# RZT2ME register map
Vendor: Renesas Electronics Corporation; Series: RZT; File version: 1.00.00
CPU: other r0p0, little endian, MPU, no FPU, VTOR, 4 interrupt priority bits, 624 interrupts
Registers are 32-bit, read-write, reset 0x0 unless marked. A register's access mark holds for its fields unless they carry their own. Offsets are from the block's base; [hi:lo] are bit positions; {n}, {i} and the like mark numbered series; 'fields as' and 'values as' point back to an identical list.

## CANFD (part 1 of 2)
Base 0x80020000
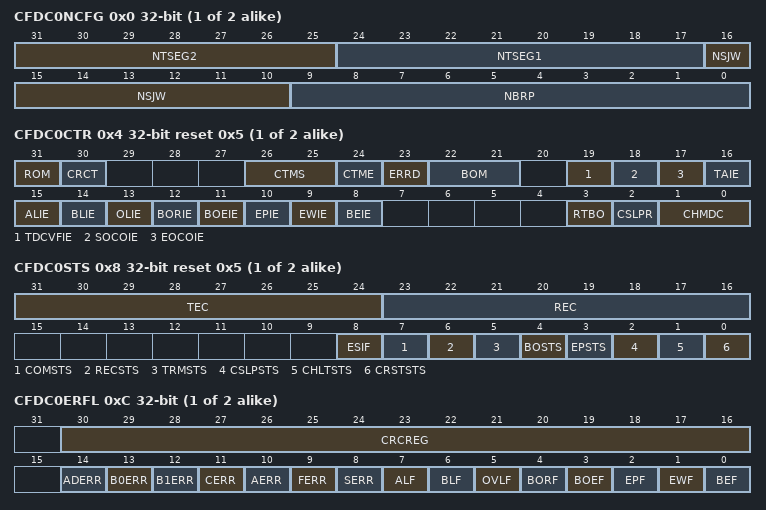
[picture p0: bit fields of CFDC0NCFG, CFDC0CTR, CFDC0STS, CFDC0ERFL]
{0x0+0x10*i} CFDC{i}NCFG (i=0..1) — Channel {i} Nominal Bit Rate Configuration Register
  [31:25] NTSEG2 — Nominal Bit Rate Time Segment 2 Control
  [24:17] NTSEG1 — Nominal Bit Rate Time Segment 1 Control
  [16:10] NSJW — Nominal Bit Rate Resynchronization Jump Width Control
  [9:0] NBRP — Nominal Bit Rate Prescaler
{0x4+0x10*i} CFDC{i}CTR (i=0..1) reset 0x5 — Channel {i} Control Register
  [31] ROM — Restricted Operation Mode Enable
    0=Restricted operation mode disabled; 1=Restricted operation mode enabled
  [30] CRCT — CRC Error Test Enable
    0=The first bit of reception ID field is not inverted; 1=The first bit of reception ID field is inverted
  [26:25] CTMS — Communication Test Mode Select
    0=Standard test mode; 1=Listen-only mode; 2=Self-test mode 0 (External loopback mode); 3=Self-test mode 1 (Internal loopback mode)
  [24] CTME — Communication Test Mode Enable
    0=Communication test mode is disabled; 1=Communication test mode is enabled
  [23] ERRD — Error Display Mode Select
    0=Error flags are displayed only for the first error information after bits [14:8] in the CFDCnERFL register are all cleared; 1=Error flag for all error information are displayed
  [22:21] BOM — Bus-Off Recovery Mode Select
    0=ISO11898-1 compliant; 1=Entry to Channel Halt mode automatically at bus-off entry; 2=Entry to Channel Halt mode automatically at bus-off end; 3=Entry to Channel Halt mode (in bus-off state) by program request
  [19] TDCVFIE — Transceiver Delay Compensation Violation Interrupt Enable
    0=Transceiver delay compensation violation interrupt disabled; 1=Transceiver delay compensation violation interrupt enabled
  [18] SOCOIE — Successful Occurrence Counter Overflow Interrupt Enable
    0=Successful occurrence counter overflow interrupt disabled; 1=Successful occurrence counter overflow interrupt enabled
  [17] EOCOIE — Error Occurrence Counter Overflow Interrupt Enable
    0=Error occurrence counter overflow interrupt disabled; 1=Error occurrence counter overflow interrupt enabled
  [16] TAIE — Transmission Abort Interrupt Enable
    0=Transmission abort interrupt disabled; 1=Transmission abort interrupt enabled
  [15] ALIE — Arbitration Lost Interrupt Enable
    0=Arbitration lost interrupt disabled; 1=Arbitration lost interrupt enabled
  [14] BLIE — Bus Lock Interrupt Enable
    0=Bus lock interrupt disabled; 1=Bus lock interrupt enabled
  [13] OLIE — Overload Interrupt Enable
    0=Overload interrupt disabled; 1=Overload interrupt enabled
  [12] BORIE — Bus-Off Recovery Interrupt Enable
    0=Bus-off recovery interrupt disabled; 1=Bus-off recovery interrupt enabled
  [11] BOEIE — Bus-Off Entry Interrupt Enable
    0=Bus-off entry interrupt disabled; 1=Bus-off entry interrupt enabled
  [10] EPIE — Error Passive Interrupt Enable
    0=Error passive interrupt disabled; 1=Error passive interrupt enabled
  [9] EWIE — Error Warning Interrupt Enable
    0=Error warning interrupt disabled; 1=Error warning interrupt enabled
  [8] BEIE — Bus Error Interrupt Enable
    0=Bus error interrupt disabled; 1=Bus error interrupt enabled
  [3] RTBO — Forcible Return from Bus-Off
  [2] CSLPR — Channel Stop Mode
    0=Other than Channel Stop mode; 1=Channel Stop mode
  [1:0] CHMDC — Mode Select
    0=Channel Communication mode; 1=Channel Reset mode; 2=Channel Halt mode; 3=Setting prohibited
{0x8+0x10*i} CFDC{i}STS (i=0..1) reset 0x5 — Channel {i} Status Register
  [31:24] TEC ro — Transmission Error Count
  [23:16] REC ro — Reception Error Count
  [8] ESIF — Error State Indication Flag
    0=No CANFD message whose ESI bit is recessive has been received; 1=At least one CANFD message whose ESI bit is recessive has been received
  [7] COMSTS ro — Communication Status Flag
    0=Communication is not ready; 1=Communication is ready
  [6] RECSTS ro — Receive Status Flag
    0=Bus idle, in transmission or bus off state; 1=In reception
  [5] TRMSTS ro — Transmit Status Flag
    0=Bus idle or in reception; 1=In transmission or bus off state
  [4] BOSTS ro — Bus-Off Status Flag
    0=Not in bus-off state; 1=In bus-off state
  [3] EPSTS ro — Error Passive Status Flag
    0=Not in error passive state; 1=In error passive state
  [2] CSLPSTS ro — Channel Stop Status Flag
    0=Not in Channel Sleep mode; 1=In Channel Sleep mode
  [1] CHLTSTS ro — Channel Halt Status Flag
    0=Not in Channel Halt mode; 1=In Channel Halt mode
  [0] CRSTSTS ro — Channel Reset Status Flag
    0=Not in Channel Reset mode; 1=In Channel Reset mode
{0xC+0x10*i} CFDC{i}ERFL (i=0..1) — Channel {i} Error Flag Register
  [30:16] CRCREG ro — CRC Calculation Data (CRC length: 15 bits)
  [14] ADERR — Acknowledge Delimiter Error Flag
    0=Channel acknowledge delimiter error not detected; 1=Channel acknowledge delimiter error detected
  [13] B0ERR — Dominant Bit Error Flag
    0=Channel dominant bit error not detected; 1=Channel dominant bit error detected
  [12] B1ERR — Recessive Bit Error Flag
    0=Channel recessive bit error not detected; 1=Channel recessive bit error detected
  [11] CERR — CRC Error Flag
    0=Channel CRC error not detected; 1=Channel CRC error detected
  [10] AERR — Acknowledge Error Flag
    0=Channel acknowledge error not detected; 1=Channel acknowledge error detected
  [9] FERR — Form Error Flag
    0=Channel form error not detected; 1=Channel form error detected
  [8] SERR — Stuff Error Flag
    0=Channel stuff error not detected; 1=Channel stuff error detected
  [7] ALF — Arbitration Lost Flag
    0=Channel arbitration-lost not detected; 1=Channel arbitration-lost detected
  [6] BLF — Bus Lock Flag
    0=Channel bus lock not detected; 1=Channel bus lock detected
  [5] OVLF — Overload Flag
    0=Channel overload not detected; 1=Channel overload detected
  [4] BORF — Bus-Off Recovery Flag
    0=Channel bus-off recovery not detected; 1=Channel bus-off recovery detected
  [3] BOEF — Bus-Off Entry Flag
    0=Channel bus-off entry not detected; 1=Channel bus-off entry detected
  [2] EPF — Error Passive Flag
    0=Channel error passive not detected; 1=Channel error passive detected
  [1] EWF — Error Warning Flag
    0=Channel error warning not detected; 1=Channel error warning detected
  [0] BEF — Bus Error Flag
    0=Channel bus error not detected; 1=Channel bus error detected
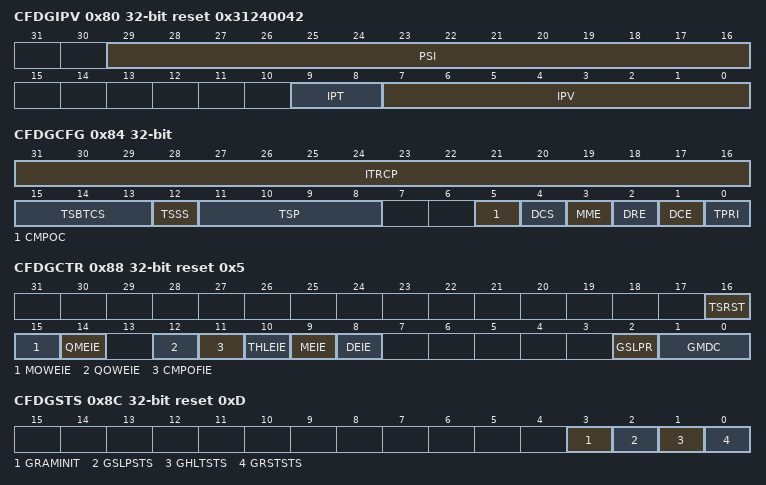
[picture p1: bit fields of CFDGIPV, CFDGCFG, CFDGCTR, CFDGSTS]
0x80 CFDGIPV ro reset 0x31240042 (reset mask 0xFFFFFEFF) — Global IP Version Register
  [29:16] PSI — Parameter Status Information
  [9:8] IPT — IP Type
    0=CAN IP; 1=CAN-FD IP
  [7:0] IPV — IP Version
0x84 CFDGCFG — Global Configuration Register
  [31:16] ITRCP — Interval Timer Reference Clock Prescaler
  [15:13] TSBTCS — Timestamp Bit Time Channel Select
    0=Select clock from channel 0; 1=Select clock from channel 1; other=Others (Setting prohibited)
  [12] TSSS — Timestamp Source Select
    0=Source clock for timestamp counter is peripheral clock; 1=Source clock for timestamp counter is bit time clock
  [11:8] TSP — Timestamp Prescaler
  [5] CMPOC — CAN-FD Message Payload Overflow Configuration
    0=Message is rejected; 1=Message payload is cut to fit to configured message size
  [4] DCS — Data Link Controller Clock Select
    0=PCLKM; 1=PCLKCAN
  [3] MME — Mirror Mode Enable
    0=Mirror mode disabled; 1=Mirror mode enabled
  [2] DRE — DLC Replacement Enable
    0=DLC replacement disabled; 1=DLC replacement enabled
  [1] DCE — DLC Check Enable
    0=DLC check disabled; 1=DLC check enabled
  [0] TPRI — Transmission Priority
    0=ID priority; 1=Message buffer number priority
0x88 CFDGCTR reset 0x5 — Global Control Register
  [16] TSRST — Timestamp Reset
    0=Timestamp not reset; 1=Timestamp reset
  [15] MOWEIE — Message Lost Error Interrupt Enable
    0=GW FIFO message lost error interrupt disabled; 1=GW FIFO message lost error interrupt enabled
  [14] QMEIE — TXQ Message Lost Error Interrupt Enable
    0=TXQ message lost error interrupt disabled; 1=TXQ message lost error interrupt enabled
  [12] QOWEIE — TXQ Message Overwrite Error Interrupt Enable
    0=TXQ message overwrite error interrupt disabled; 1=TXQ message overwrite error interrupt enabled
  [11] CMPOFIE — CAN-FD Message Payload Overflow Flag Interrupt Enable
    0=CAN-FD message payload overflow flag interrupt disabled; 1=CAN-FD message payload overflow flag interrupt enabled
  [10] THLEIE — TX History List Entry Lost Interrupt Enable
    0=TX history list entry lost interrupt disabled; 1=TX history list entry lost interrupt enabled
  [9] MEIE — Message Lost Error Interrupt Enable
    0=Message lost error interrupt disabled; 1=Message lost error interrupt enabled
  [8] DEIE — DLC Check Interrupt Enable
    0=DLC check interrupt disabled; 1=DLC check interrupt enabled
  [2] GSLPR — Global Sleep Request
    0=Global sleep request disabled; 1=Global sleep request enabled
  [1:0] GMDC — Global Mode Control
    0=Global operation mode request; 1=Global reset mode request; 2=Global halt mode request; 3=Keep current value
0x8C CFDGSTS ro reset 0xD — Global Status Register
  [3] GRAMINIT — Global RAM Initialization
    0=RAM initialization is complete; 1=RAM initialization is ongoing
  [2] GSLPSTS — Global Sleep Status
    0=Not in Sleep mode; 1=In Sleep mode
  [1] GHLTSTS — Global Halt Status
    0=Not in Halt mode; 1=In Halt mode
  [0] GRSTSTS — Global Reset Status
    0=Not in Reset mode; 1=In Reset mode
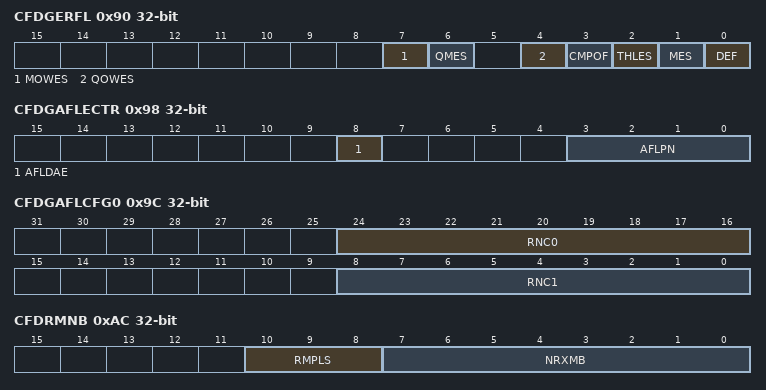
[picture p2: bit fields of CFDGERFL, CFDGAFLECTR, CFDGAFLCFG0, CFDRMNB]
0x90 CFDGERFL — Global Error Flag Register
  [7] MOWES ro — Message Overwrite Error Status
    0=Message overwrite error not detected; 1=Message overwrite error detected
  [6] QMES ro — TXQ Message Lost Error Status
    0=TXQ message lost error not detected; 1=TXQ message lost error detected
  [4] QOWES ro — TXQ Message Overwrite Error Status
    0=TXQ message overwrite error not detected; 1=TXQ message overwrite error detected
  [3] CMPOF — CAN-FD Message Payload Overflow Flag
    0=CAN-FD message payload overflow not detected; 1=CAN-FD message payload overflow detected
  [2] THLES ro — TX History List Entry Lost Error Status
    0=TX history list entry lost error not detected; 1=TX history list entry lost error detected
  [1] MES ro — Message Lost Error Status
    0=Message lost error not detected; 1=Message lost error detected
  [0] DEF — DLC Error Flag
    0=DLC error not detected; 1=DLC error detected
0x94 CFDGTSC ro — Global Timestamp Counter Register
  [15:0] TS — Timestamp value
0x98 CFDGAFLECTR — Global Acceptance Filter List Entry Control Register
  [8] AFLDAE — Acceptance Filter List Data Access Enable
    0=Acceptance Filter List data access disabled; 1=Acceptance Filter List data access enabled
  [3:0] AFLPN — Acceptance Filter List Page Number
0x9C CFDGAFLCFG0 — Global Acceptance Filter List Configuration Register 0
  [24:16] RNC0 — Rule Number for Channel 0
  [8:0] RNC1 — Rule Number for Channel 1
0xAC CFDRMNB — RX Message Buffer Number Register
  [10:8] RMPLS — Reception Message Buffer Payload Data Size
    0=8 bytes; 1=12 bytes; 2=16 bytes; 3=20 bytes; 4=24 bytes; 5=32 bytes; 6=48 bytes; 7=64 bytes
  [7:0] NRXMB — Number of RX Message Buffers
0xB0 CFDRMND0 — RX Message Buffer New Data Register 0
  [31:0] RMNS — RX Message Buffer New Data Status
    0=New data not stored in corresponding RX message buffer; 1=New data stored in corresponding RX message buffer
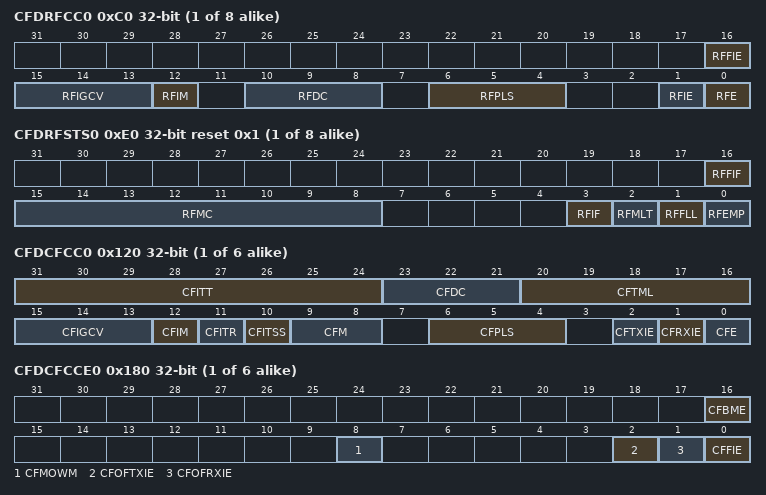
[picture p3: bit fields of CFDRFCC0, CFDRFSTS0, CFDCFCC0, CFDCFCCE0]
{0xC0+4i} CFDRFCC{i} (i=0..7) — RX FIFO Configuration/Control Register {i}
  [16] RFFIE — RX FIFO Full Interrupt Enable
    0=FIFO interrupt generation disabled; 1=FIFO interrupt generation enabled
  [15:13] RFIGCV — RX FIFO Interrupt Generation Counter Value
    0=Interrupt generated when FIFO is 1/8th full; 1=Interrupt generated when FIFO is 1/4th full; 2=Interrupt generated when FIFO is 3/8th full; 3=Interrupt generated when FIFO is 1/2 full; 4=Interrupt generated when FIFO is 5/8th full; 5=Interrupt generated when FIFO is 3/4th full; 6=Interrupt generated when FIFO is 7/8th full; 7=Interrupt generated when FIFO is full
  [12] RFIM — RX FIFO Interrupt Mode
    0=Interrupt generated when RX FIFO counter reaches RFIGCV value from values smaller than RFIGCV; 1=Interrupt generated at the end of every received message storage
  [10:8] RFDC — RX FIFO Depth Configuration
    0=FIFO Depth = 0 messages; 1=FIFO Depth = 4 messages; 2=FIFO Depth = 8 messages; 3=FIFO Depth = 16 messages; 4=FIFO Depth = 32 messages; 5=FIFO Depth = 48 messages; 6=FIFO Depth = 64 messages; 7=FIFO Depth = 128 messages
  [6:4] RFPLS — Rx FIFO Payload Data Size Configuration
    values as CFDRMNB.RMPLS
  [1] RFIE — RX FIFO Interrupt Enable
    values as RFFIE
  [0] RFE — RX FIFO Enable
    0=FIFO disabled; 1=FIFO enabled
{0xE0+4i} CFDRFSTS{i} (i=0..7) reset 0x1 — RX FIFO Status Register {i}
  [16] RFFIF — RX FIFO Full Interrupt Flag
    0=FIFO full interrupt condition not satisfied; 1=FIFO full interrupt condition satisfied
  [15:8] RFMC ro — RX FIFO Message Count
  [3] RFIF — RX FIFO Interrupt Flag
    0=FIFO interrupt condition not satisfied; 1=FIFO interrupt condition satisfied
  [2] RFMLT — RX FIFO Message Lost
    0=No message lost in FIFO; 1=FIFO message lost
  [1] RFFLL ro — RX FIFO Full
    0=FIFO not full; 1=FIFO full
  [0] RFEMP ro — RX FIFO Empty
    0=FIFO not empty; 1=FIFO empty
{0x100+4i} CFDRFPCTR{i} (i=0..7) — RX FIFO Pointer Control Register {i}
  [7:0] RFPC — RX FIFO Pointer Control
{0x120+4i} CFDCFCC{i} (i=0..5) — Common FIFO Configuration/Control Register {i}
  [31:24] CFITT — Common FIFO Interval Transmission Time
  [23:21] CFDC — Common FIFO Depth Configuration
    values as CFDRFCC0.RFDC
  [20:16] CFTML — Common FIFO TX Message Buffer Link
  [15:13] CFIGCV — Common FIFO Interrupt Generation Counter Value
    values as CFDRFCC0.RFIGCV
  [12] CFIM — Common FIFO Interrupt Mode
    0=RX FIFO mode: RX interrupt generated when Common FIFO counter reaches CFIGCV value from a lower value TX FIFO mode: TX interrupt generated when Common FIFO transmits the last message successfully GW FIFO mode: For RX interrupt flag: Interrupt generated when FIFO counter increments and reaches the value configured in CFIGCV For TX interrupt flag: Interrupt generated when FIFO transmits the last message successfully; 1=RX FIFO mode: RX interrupt generated at the end of every received message storage TX FIFO mode: TX interrupt generated for every successfully transmitted message GW FIFO mode: For RX interrupt flag: Interrupt generated when a message is stored in the FIFO For TX interrupt flag: Interrupt generated when a message is successfully transmitted from the FIFO
  [11] CFITR — Common FIFO Interval Timer Resolution
    0=Reference clock period * 1; 1=Reference clock period * 10
  [10] CFITSS — Common FIFO Interval Timer Source Select
    0=Reference clock (* 1 / * 10 period); 1=Bit time clock of related channel (FIFO is linked to fixed channel)
  [9:8] CFM — Common FIFO Mode
    0=RX FIFO mode; 1=TX FIFO mode; 2=CAN - CAN GW FIFO mode
  [6:4] CFPLS — Common FIFO Payload Data Size Configuration
    values as CFDRMNB.RMPLS
  [2] CFTXIE — Common FIFO TX Interrupt Enable
    0=FIFO interrupt generation disabled for Frame TX; 1=FIFO interrupt generation enabled for Frame TX
  [1] CFRXIE — Common FIFO RX Interrupt Enable
    0=FIFO interrupt generation disabled for Frame RX; 1=FIFO interrupt generation enabled for Frame RX
  [0] CFE — Common FIFO Enable
    0=FIFO disabled; 1=FIFO enabled
{0x180+4i} CFDCFCCE{i} (i=0..5) — Common FIFO Configuration/Control Enhancement Register {i}
  [16] CFBME — Common FIFO Buffering Mode Enable
    0=Transmission from Common FIFO; 1=Transmission halt from Common FIFO
  [8] CFMOWM — Common FIFO Message Overwrite Mode
    0=Message discarded mode; 1=Message overwrite mode
  [2] CFOFTXIE — Common FIFO One Frame Transmission Interrupt Enable
    0=One Frame TX interrupt generation disabled; 1=One Frame TX interrupt generation enabled
  [1] CFOFRXIE — Common FIFO One Frame Reception Interrupt Enable
    0=One Frame RX interrupt generation disabled; 1=One Frame RX interrupt generation enabled
  [0] CFFIE — Common FIFO Full Interrupt Enable
    0=FIFO Interrupt generation disabled; 1=FIFO Interrupt generation enabled
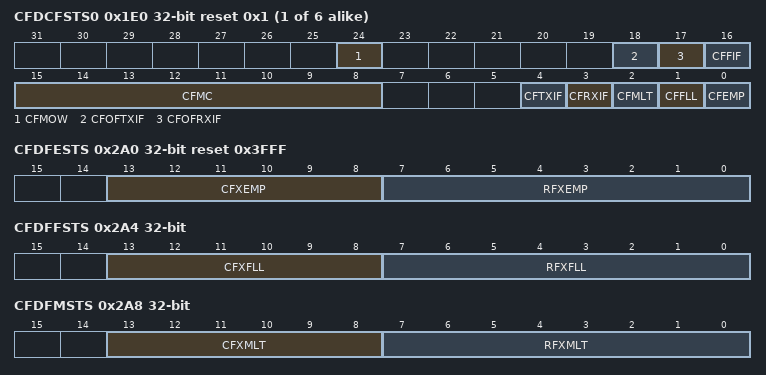
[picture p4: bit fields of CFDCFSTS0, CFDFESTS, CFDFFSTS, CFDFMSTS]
{0x1E0+4i} CFDCFSTS{i} (i=0..5) reset 0x1 — Common FIFO Status Register {i}
  [24] CFMOW — Common FIFO Message Overwrite
    0=No message overwrite occurred in FIFO; 1=Message overwrite occurred in FIFO
  [18] CFOFTXIF — Common FIFO One Frame Transmission Interrupt Flag
  [17] CFOFRXIF — Common FIFO One Frame Reception Interrupt Flag
  [16] CFFIF — Common FIFO Full Interrupt Flag
    0=Interrupt condition not satisfied for FIFO full interrupt; 1=Interrupt condition satisfied for FIFO full interrupt
  [15:8] CFMC ro — Common FIFO Message Count
  [4] CFTXIF — Common TX FIFO Interrupt Flag
    0=FIFO interrupt condition not satisfied after frame transmission; 1=FIFO Interrupt condition satisfied after frame transmission
  [3] CFRXIF — Common RX FIFO Interrupt Flag
    0=FIFO interrupt condition not satisfied after frame reception; 1=FIFO interrupt condition satisfied after frame reception
  [2] CFMLT — Common FIFO Message Lost
    0=FIFO message not lost; 1=FIFO message lost
  [1] CFFLL ro — Common FIFO Full
    0=FIFO not full; 1=FIFO full
  [0] CFEMP ro — Common FIFO Empty
    0=FIFO not empty; 1=FIFO empty
{0x240+4i} CFDCFPCTR{i} (i=0..5) wo — Common FIFO Pointer Control Register {i}
  [7:0] CFPC — Common FIFO Pointer Control
0x2A0 CFDFESTS ro reset 0x3FFF — FIFO Empty Status Register
  [13:8] CFXEMP — Common FIFO Empty Status
    0=Corresponding FIFO not empty; 1=Corresponding FIFO empty
  [7:0] RFXEMP — RX FIFO Empty Status
    0=Corresponding FIFO not empty; 1=Corresponding FIFO empty
0x2A4 CFDFFSTS ro — FIFO Full Status Register
  [13:8] CFXFLL — Common FIFO Full Status
    0=Corresponding FIFO not full; 1=Corresponding FIFO full
  [7:0] RFXFLL — RX FIFO Full Status
    0=Corresponding FIFO not full; 1=Corresponding FIFO full
0x2A8 CFDFMSTS ro — FIFO Message Lost Status Register
  [13:8] CFXMLT — Common FIFO Message Lost Status
    0=Corresponding FIFO Message Lost flag not set; 1=Corresponding FIFO Message Lost flag set
  [7:0] RFXMLT — RX FIFO Message Lost Status
    values as CFXMLT
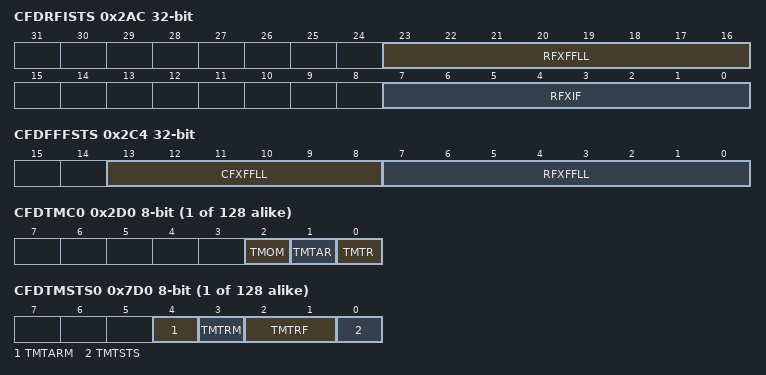
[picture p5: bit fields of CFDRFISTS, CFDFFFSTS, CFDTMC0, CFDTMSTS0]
0x2AC CFDRFISTS ro — RX FIFO Interrupt Flag Status Register
  [23:16] RFXFFLL — RX FIFO[x] Interrupt Full Flag Status
    0=Corresponding RX FIFO Interrupt Full flag not set; 1=Corresponding RX FIFO Interrupt Full flag set
  [7:0] RFXIF — RX FIFO[x] Interrupt Flag Status
    0=Corresponding RX FIFO Interrupt flag not set; 1=Corresponding RX FIFO Interrupt flag set
0x2B0 CFDCFRISTS ro — Common FIFO RX Interrupt Flag Status Register
  [5:0] CFXRXIF — Common FIFO RX Interrupt Flag Status
    0=Corresponding Common FIFO RX Interrupt flag not set; 1=Corresponding Common FIFO RX Interrupt flag set
0x2B4 CFDCFTISTS ro — Common FIFO TX Interrupt Flag Status Register
  [5:0] CFXTXIF — Common FIFO TX Interrupt Flag Status
    0=Corresponding Common FIFO TX Interrupt flag not set; 1=Corresponding Common FIFO TX Interrupt flag set
0x2B8 CFDCFOFRISTS ro — Common FIFO One Frame RX Interrupt Flag Status Register
  [5:0] CFXOFRXIF — Common FIFO One Frame RX Interrupt Flag Status
    0=Corresponding Common FIFO One Frame RX Interrupt flag not set; 1=Corresponding Common FIFO One Frame RX Interrupt flag set
0x2BC CFDCFOFTISTS ro — Common FIFO One Frame TX Interrupt Flag Status Register
  [5:0] CFXOFTXIF — Common FIFO One Frame TX Interrupt Flag Status
    0=Corresponding Common FIFO One Frame TX Interrupt flag not set; 1=Corresponding Common FIFO One Frame TX Interrupt flag set
0x2C0 CFDCFMOWSTS ro — Common FIFO Message Overwrite Status Register
  [5:0] CFXMOW — Common FIFO Massage Overwrite Status
    0=Corresponding FIFO Overwrite flag not set; 1=Corresponding FIFO Overwrite flag set
0x2C4 CFDFFFSTS ro — FIFO FDC Full Status Register
  [13:8] CFXFFLL — COMMON FIFO FDC Level Full Status
    0=Corresponding FIFO full interrupt not set; 1=Corresponding FIFO full interrupt set
  [7:0] RFXFFLL — RX FIFO FDC Level Full Status
    values as CFXFFLL
{0x2D0+i} CFDTMC{i} (i=0..127) 8-bit — TX Message Buffer Control Register {i}
  [2] TMOM — TX Message Buffer One-shot Mode
    0=TX message buffer not configured in one-shot mode; 1=TX message buffer configured in one-shot mode
  [1] TMTAR — TX Message Buffer Transmission Abort Request
    0=TX message buffer transmission request abort not requested; 1=TX message buffer transmission request abort requested
  [0] TMTR — TX Message Buffer Transmission Request
    0=TX Message buffer transmission not requested; 1=TX message buffer transmission requested
{0x7D0+i} CFDTMSTS{i} (i=0..127) 8-bit — TX Message Buffer Status Register {i}
  [4] TMTARM ro — TX Message Buffer Transmission Abort Request Mirrored
    values as CFDTMC0.TMTAR
  [3] TMTRM ro — TX Message Buffer Transmission Request Mirrored
    0=TX message buffer transmission not requested; 1=TX message buffer transmission requested
  [2:1] TMTRF — TX Message Buffer Transmission Result Flag
    0=No result; 1=Transmission aborted from the TX message buffer; 2=Transmission successful from the TX message buffer and transmission abort was not requested; 3=Transmission successful from the TX message buffer and transmission abort was requested
  [0] TMTSTS ro — TX Message Buffer Transmission Status
    0=No on-going transmission; 1=On-going transmission
{0xCD0+4i} CFDTMTRSTS{i} (i=0..3) ro — TX Message Buffer Transmission Request Status Register {i}
  [15:0] TMTRSTS — TX Message Buffer Transmission Request Status
    0=Transmission not requested for corresponding TX message buffer; 1=Transmission requested for corresponding TX message buffer
{0xD70+4i} CFDTMTARSTS{i} (i=0..3) ro — TX Message Buffer Transmission Abort Request Status Register {i}
  [15:0] TMTARSTS — TX Message Buffer Transmission Abort Request Status
    0=Transmission abort not requested for corresponding TX message buffer; 1=Transmission abort requested for corresponding TX message buffer
{0xE10+4i} CFDTMTCSTS{i} (i=0..3) ro — TX Message Buffer Transmission Completion Status Register {i}
  [15:0] TMTCSTS — TX Message Buffer Transmission Completion Status
    0=Transmission not completed for corresponding TX message buffer; 1=Transmission completed for corresponding TX message buffer
{0xEB0+4i} CFDTMTASTS{i} (i=0..3) ro — TX Message Buffer Transmission Abort Status Register {i}
  [15:0] TMTASTS — TX Message Buffer Transmission Abort Status
    0=Transmission not aborted for corresponding TX message buffer; 1=Transmission aborted for corresponding TX message buffer
{0xF50+4i} CFDTMIEC{i} (i=0..3) — TX Message Buffer Transmission Interrupt Enable Register {i}
  [15:0] TMIE — TX Message Buffer Interrupt Enable
    0=TX message buffer interrupt disabled for corresponding TX message buffer; 1=TX message buffer interrupt enabled for corresponding TX message buffer
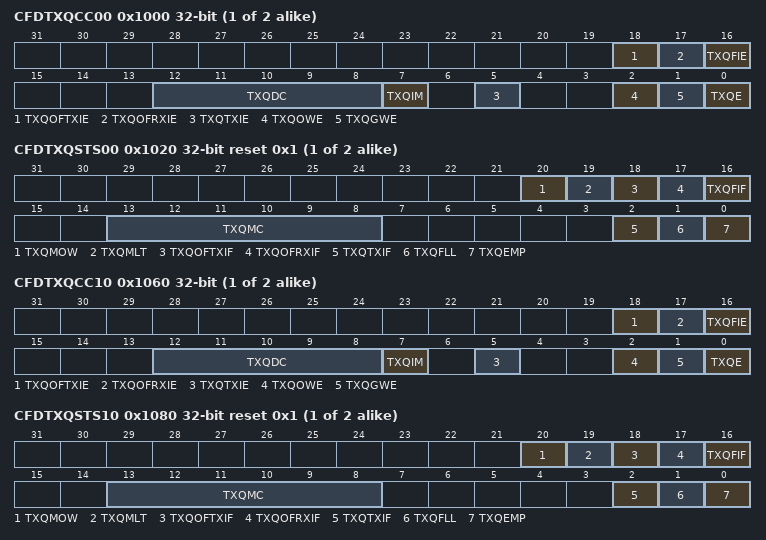
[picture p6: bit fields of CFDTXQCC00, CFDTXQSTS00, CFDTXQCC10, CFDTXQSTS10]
{0x1000+4i} CFDTXQCC0{i} (i=0..1) — TX Queue Configuration/Control Register 0{i}
  [18] TXQOFTXIE — TXQ One Frame Transmission Interrupt Enable
    values as CFDCFCCE0.CFOFTXIE
  [17] TXQOFRXIE — TXQ One Frame Reception Interrupt Enable
    values as CFDCFCCE0.CFOFRXIE
  [16] TXQFIE — TXQ Full Interrupt Enable
    0=TX Queue full interrupt generation disabled; 1=TX Queue full interrupt generation enabled
  [12:8] TXQDC — TX Queue Depth Configuration
  [7] TXQIM — TX Queue Interrupt Mode
    0=When the last message is successfully transmitted; 1=At every successful transmission
  [5] TXQTXIE — TX Queue TX Interrupt Enable
    0=TX Queue TX interrupt disabled; 1=TX Queue TX interrupt enabled
  [2] TXQOWE — TX Queue Overwrite Mode Enable
    0=TX Queue OW mode disabled; 1=TX Queue OW mode enabled
  [1] TXQGWE — TX Queue Gateway Mode Enable
    0=TX Queue GW mode disabled; 1=TX Queue GW mode enabled
  [0] TXQE — TX Queue Enable
    0=TX Queue disabled; 1=TX Queue enabled
{0x1020+4i} CFDTXQSTS0{i} (i=0..1) reset 0x1 — TX Queue Status Register 0{i}
  [20] TXQMOW — TXQ Message Overwrite
    0=No message overwrite in TXQ; 1=Message overwrite in TXQ
  [19] TXQMLT — TXQ Message Lost
    0=No message lost in TXQ; 1=TXQ message lost
  [18] TXQOFTXIF — TXQ One Frame Transmission Interrupt Flag
  [17] TXQOFRXIF — TXQ One Frame Reception Interrupt Flag
  [16] TXQFIF — TXQ Full Interrupt Flag
  [13:8] TXQMC ro — TX Queue Message Count
  [2] TXQTXIF — TX Queue TX Interrupt Flag
    0=TX Queue interrupt condition not satisfied after a frame TX; 1=TX Queue interrupt condition satisfied after a frame TX
  [1] TXQFLL ro — TX Queue Full
    0=TX Queue not full; 1=TX Queue full
  [0] TXQEMP ro — TX Queue Empty
    0=TX Queue not empty; 1=TX Queue empty
{0x1040+4i} CFDTXQPCTR0{i} (i=0..1) wo — TX Queue Pointer Control Register 0{i}
  [7:0] TXQPC — TX Queue Pointer Control
{0x1060+4i} CFDTXQCC1{i} (i=0..1) — TX Queue Configuration/Control Register 1{i}
  fields as CFDTXQCC00
{0x1080+4i} CFDTXQSTS1{i} (i=0..1) reset 0x1 — TX Queue Status Register 1{i}
  fields as CFDTXQSTS00
{0x10A0+4i} CFDTXQPCTR1{i} (i=0..1) wo — TX Queue Pointer Control Register 1{i}
  [7:0] TXQPC — TX Queue Pointer Control
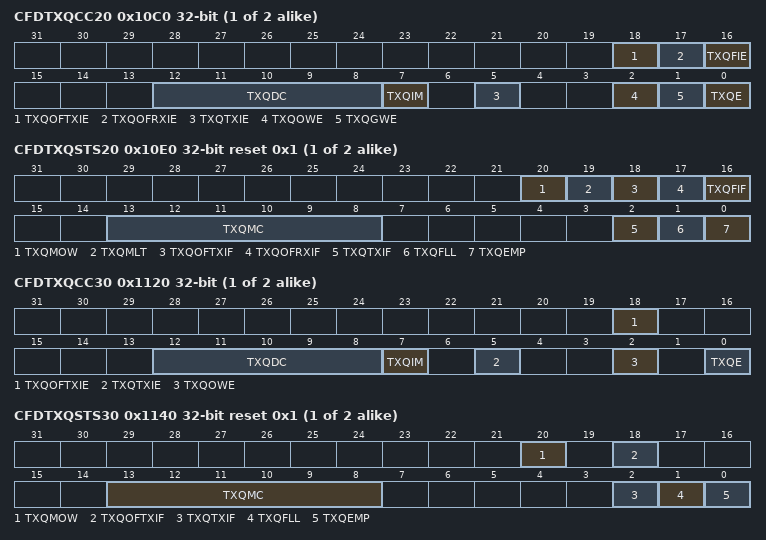
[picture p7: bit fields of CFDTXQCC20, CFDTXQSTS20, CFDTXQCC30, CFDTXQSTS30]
{0x10C0+4i} CFDTXQCC2{i} (i=0..1) — TX Queue Configuration/Control Register 2{i}
  fields as CFDTXQCC00
{0x10E0+4i} CFDTXQSTS2{i} (i=0..1) reset 0x1 — TX Queue Status Register 2{i}
  fields as CFDTXQSTS00
{0x1100+4i} CFDTXQPCTR2{i} (i=0..1) wo — TX Queue Pointer Control Register 2{i}
  [7:0] TXQPC — TX Queue Pointer Control
{0x1120+4i} CFDTXQCC3{i} (i=0..1) — TX Queue Configuration/Control Register 3{i}
  [18] TXQOFTXIE — TXQ One Frame Transmission Interrupt Enable
    values as CFDCFCCE0.CFOFTXIE
  [12:8] TXQDC — TX Queue Depth Configuration
  [7] TXQIM — TX Queue Interrupt Mode
    values as CFDTXQCC00.TXQIM
  [5] TXQTXIE — TX Queue TX Interrupt Enable
    values as CFDTXQCC00.TXQTXIE
  [2] TXQOWE — TX Queue Overwrite Mode Enable
    0=TX Queue OW mode disabled; 1=TX Queue OW mode enabled
  [0] TXQE — TX Queue Enable
    0=TX Queue disabled; 1=TX Queue enabled
{0x1140+4i} CFDTXQSTS3{i} (i=0..1) reset 0x1 — TX Queue Status Register 3{i}
  [20] TXQMOW — TXQ Message Overwrite
    0=No message overwrite in TXQ; 1=Message overwrite in TXQ
  [18] TXQOFTXIF — TXQ One Frame Transmission Interrupt Flag
  [13:8] TXQMC ro — TX Queue Message Count
  [2] TXQTXIF — TX Queue TX Interrupt Flag
    values as CFDTXQSTS00.TXQTXIF
  [1] TXQFLL ro — TX Queue Full
    0=TX Queue not full; 1=TX Queue full
  [0] TXQEMP ro — TX Queue Empty
    0=TX Queue not empty; 1=TX Queue empty
{0x1160+4i} CFDTXQPCTR3{i} (i=0..1) wo — TX Queue Pointer Control Register 3{i}
  [7:0] TXQPC — TX Queue Pointer Control
0x1180 CFDTXQESTS ro reset 0xFF — TX Queue Empty Status Register
  [7:0] TXQxEMP — TXQ Empty Status
    0=TXQ not empty; 1=TXQ empty
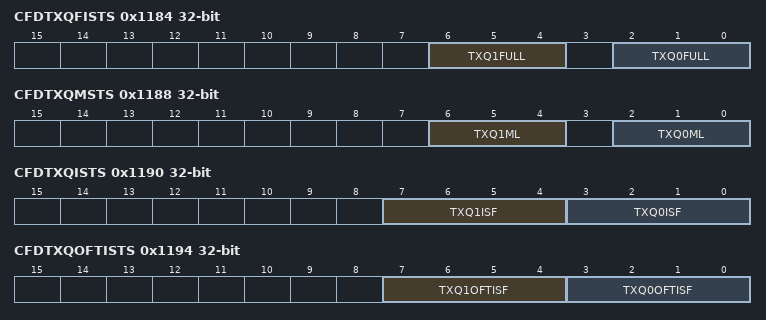
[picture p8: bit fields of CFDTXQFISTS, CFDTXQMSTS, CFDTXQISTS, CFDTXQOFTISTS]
0x1184 CFDTXQFISTS ro — TX Queue Full Interrupt Status Register
  [6:4] TXQ1FULL — TXQ Full Interrupt Status Flag for Channel 1
    0=TXQ full interrupt not set; 1=TXQ full interrupt set
  [2:0] TXQ0FULL — TXQ Full Interrupt Status Flag for Channel 0
    0=TXQ full interrupt not set; 1=TXQ full interrupt set
0x1188 CFDTXQMSTS ro — TX Queue Message Lost Status Register
  [6:4] TXQ1ML — TXQ Message Lost Status Flag for Channel 1
    0=TXQ message lost flag not set; 1=TXQ message lost flag set
  [2:0] TXQ0ML — TXQ Message Lost Status Flag for Channel 0
    0=TXQ message lost flag not set; 1=TXQ message lost flag set
0x1190 CFDTXQISTS ro — TX Queue Interrupt Status Register
  [7:4] TXQ1ISF — TXQ Interrupt Status Flag for Channel 1
    0=TXQ Interrupt flag not set; 1=TXQ Interrupt flag set
  [3:0] TXQ0ISF — TXQ Interrupt Status Flag for Channel 0
    0=TXQ Interrupt flag not set; 1=TXQ Interrupt flag set
0x1194 CFDTXQOFTISTS ro — TX Queue One Frame TX Interrupt Status Register
  [7:4] TXQ1OFTISF — TXQ One Frame TX Interrupt Status Flag for Channel 1
    0=TXQ One Frame TX Interrupt flag not set; 1=TXQ One Frame TX Interrupt flag set
  [3:0] TXQ0OFTISF — TXQ One Frame TX Interrupt Status Flag for Channel 0
    values as TXQ1OFTISF
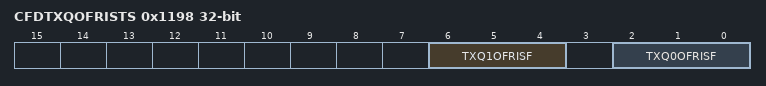
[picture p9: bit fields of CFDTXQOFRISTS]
0x1198 CFDTXQOFRISTS ro — TX Queue One Frame RX Interrupt Status Register
  [6:4] TXQ1OFRISF — TXQ One Frame RX Interrupt Status Flag for Channel 1
    0=TXQ One Frame RX Interrupt flag not set; 1=TXQ One Frame RX Interrupt flag set
  [2:0] TXQ0OFRISF — TXQ One Frame RX Interrupt Status Flag for Channel 0
    values as TXQ1OFRISF
